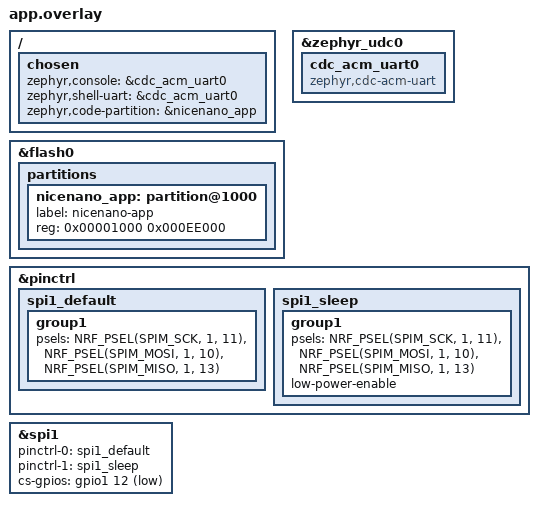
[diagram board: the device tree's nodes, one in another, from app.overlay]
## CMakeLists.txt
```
cmake_minimum_required(VERSION 3.20.0)
find_package(Zephyr REQUIRED HINTS $ENV{ZEPHYR_BASE})
project(nrf52840_nicenano_spi_loopback)
target_sources(app PRIVATE src/main.c ../nrf52840_nicenano_common/ael_usb.c)
```

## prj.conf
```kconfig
CONFIG_GPIO=y
CONFIG_SPI=y
CONFIG_SERIAL=y
CONFIG_CONSOLE=y
CONFIG_UART_CONSOLE=y
CONFIG_STDOUT_CONSOLE=y
CONFIG_PRINTK=y
CONFIG_USB_DEVICE_STACK_NEXT=y
CONFIG_USBD_CDC_ACM_CLASS=y
CONFIG_CDC_ACM_SERIAL_INITIALIZE_AT_BOOT=y
CONFIG_CDC_ACM_SERIAL_PID=0x000E
CONFIG_CDC_ACM_SERIAL_PRODUCT_STRING="AEL nRF52840 SPI Loopback"
CONFIG_BUILD_OUTPUT_UF2=y
CONFIG_BUILD_OUTPUT_UF2_FAMILY_ID="0x239A00B3"
CONFIG_FLASH_LOAD_OFFSET=0x1000
CONFIG_FLASH_LOAD_SIZE=0xEE000
```

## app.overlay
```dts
/*
 * SPI1: SCK=P1.11, MOSI=P1.10, MISO=P1.13, CS=P1.12
 * Loopback: wire P1.10 (MOSI) → P1.13 (MISO)
 * Console: USB CDC
 */

/ {
    chosen {
        zephyr,console = &cdc_acm_uart0;
        zephyr,shell-uart = &cdc_acm_uart0;
        zephyr,code-partition = &nicenano_app;
    };
};

&flash0 {
    partitions {
        nicenano_app: partition@1000 {
            label = "nicenano-app";
            reg = <0x00001000 0x000EE000>;
        };
    };
};

&zephyr_udc0 {
    cdc_acm_uart0: cdc_acm_uart0 {
        compatible = "zephyr,cdc-acm-uart";
    };
};

&pinctrl {
    spi1_default: spi1_default {
        group1 {
            psels = <NRF_PSEL(SPIM_SCK,  1, 11)>,
                    <NRF_PSEL(SPIM_MOSI, 1, 10)>,
                    <NRF_PSEL(SPIM_MISO, 1, 13)>;
        };
    };
    spi1_sleep: spi1_sleep {
        group1 {
            psels = <NRF_PSEL(SPIM_SCK,  1, 11)>,
                    <NRF_PSEL(SPIM_MOSI, 1, 10)>,
                    <NRF_PSEL(SPIM_MISO, 1, 13)>;
            low-power-enable;
        };
    };
};

&spi1 {
    status = "okay";
    pinctrl-0 = <&spi1_default>;
    pinctrl-1 = <&spi1_sleep>;
    pinctrl-names = "default", "sleep";
    cs-gpios = <&gpio1 12 GPIO_ACTIVE_LOW>;
};
```

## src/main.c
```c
/*
 * AEL Stage 2 — nRF52840 nice!nano SPI loopback
 *
 * Wiring: P1.13 (MOSI, PIN16) ←→ P1.11 (MISO, PIN15)   [1 wire, adjacent right-column pins]
 *
 * Sends 32 bytes via SPI1, receives on MISO (shorted to MOSI), verifies.
 * Reports: [SPI] rx_match=%d/%d PASS|FAIL
 *          AEL_SPI_LOOPBACK_PASS|FAIL
 */

#include <zephyr/kernel.h>
#include <zephyr/sys/printk.h>
#include <zephyr/drivers/spi.h>
#include <string.h>
#include "../../nrf52840_nicenano_common/ael_usb.h"

#define SPI_NODE DT_NODELABEL(spi1)
#define BUF_LEN  32

static const struct spi_config spi_cfg = {
    .frequency = 1000000,
    .operation = SPI_WORD_SET(8) | SPI_TRANSFER_MSB | SPI_OP_MODE_MASTER,
    .slave     = 0,
    .cs        = {
        .gpio  = SPI_CS_GPIOS_DT_SPEC_GET(DT_NODELABEL(spi1)),
        .delay = 0,
    },
};

int main(void)
{
    ael_usb_init();
    k_msleep(1500);

    const struct device *spi_dev = DEVICE_DT_GET(SPI_NODE);
    if (!device_is_ready(spi_dev)) {
        printk("[SPI] device_not_ready FAIL\n");
        printk("AEL_SPI_LOOPBACK_FAIL\n");
        while (1) {
            if (atomic_get(&ael_bl_flag)) { k_msleep(50); ael_enter_bootloader(); }
            k_msleep(3000);
        }
    }

    uint8_t tx_buf[BUF_LEN], rx_buf[BUF_LEN];
    for (int i = 0; i < BUF_LEN; i++) tx_buf[i] = (uint8_t)(0x55 ^ i);
    memset(rx_buf, 0, sizeof(rx_buf));

    struct spi_buf tx = { .buf = tx_buf, .len = BUF_LEN };
    struct spi_buf rx = { .buf = rx_buf, .len = BUF_LEN };
    struct spi_buf_set tx_set = { .buffers = &tx, .count = 1 };
    struct spi_buf_set rx_set = { .buffers = &rx, .count = 1 };

    printk("AEL_SPI_LOOPBACK_START\n");

    int ret = spi_transceive(spi_dev, &spi_cfg, &tx_set, &rx_set);
    bool pass = false;
    if (ret != 0) {
        printk("[SPI] transceive_err=%d FAIL\n", ret);
    } else {
        int match = 0;
        for (int i = 0; i < BUF_LEN; i++) {
            if (rx_buf[i] == tx_buf[i]) match++;
        }
        pass = (match == BUF_LEN);
        printk("[SPI] rx_match=%d/%d %s\n", match, BUF_LEN, pass ? "PASS" : "FAIL");
    }

    while (1) {
        if (atomic_get(&ael_bl_flag)) { k_msleep(50); ael_enter_bootloader(); }
        printk("AEL_SPI_LOOPBACK_%s\n", pass ? "PASS" : "FAIL");
        k_msleep(3000);
    }
    return 0;
}
```
